# nRF7140_graphics register map
Vendor: Nordic Semiconductor; Series: nRF71; File version: 1
CPU: CM33 r0p4, little endian, MPU, FPU, 3 interrupt priority bits, 480 interrupts
Registers are 32-bit, read-write, reset 0x0 unless marked. A register's access mark holds for its fields unless they carry their own. Offsets are from the block's base; [hi:lo] are bit positions; lines under a group give offsets from that group; {n}, {i} and the like mark numbered series; 'fields as' and 'values as' point back to an identical list.

## GLOBAL_PWM120_NS — Pulse width modulation unit 0
Base 0x4F8E4000
Same registers: GLOBAL_PWM130_NS 0x4F9A4000, GLOBAL_PWM131_NS 0x4F9B4000, GLOBAL_PWM132_NS 0x4F9C4000, GLOBAL_PWM133_NS 0x4F9D4000, GLOBAL_PWM120_S 0x5F8E4000, GLOBAL_PWM130_S 0x5F9A4000, GLOBAL_PWM131_S 0x5F9B4000, GLOBAL_PWM132_S 0x5F9C4000, GLOBAL_PWM133_S 0x5F9D4000
0x00 TASKS_START wo — Starts PWM pulse generation with the last loaded values
  [0] TASKS_START
    1=Trigger task
0x04 TASKS_STOP wo — Stops PWM pulse generation on all channels at the end of current PWM period, and stops sequence playback
  [0] TASKS_STOP
    1=Trigger task
0x08 TASKS_NEXTSTEP wo — Steps by one value in the current sequence on all enabled channels if DECODER.MODE=NextStep. Does not cause PWM generation to start if not running.
  [0] TASKS_NEXTSTEP
    1=Trigger task
0x0C TASKS_SEQABORT wo — (Gracefully) aborts the playback of the current sequence or the current end delay
  [0] TASKS_SEQABORT
    1=Trigger task
0x10 TASKS_DMA group — Peripheral tasks.
  {0x0+8j} SEQ[{j}] (j=0..1) group — Peripheral tasks.
    0x00 START wo — Description cluster: Starts operation using easyDMA to load the values. See peripheral description for operation using easyDMA.
      [0] START — Starts operation using easyDMA to load the values. See peripheral description for operation using easyDMA.
        1=Trigger task
    0x04 STOP wo — Description cluster: Stops operation using easyDMA. This does not trigger an END event. After a STOP task, the easyDMA (channel) will also enter its lowest required power level.
      [0] STOP — Stops operation using easyDMA. This does not trigger an END event. After a STOP task, the easyDMA (channel) will also enter its lowest required power level.
        1=Trigger task
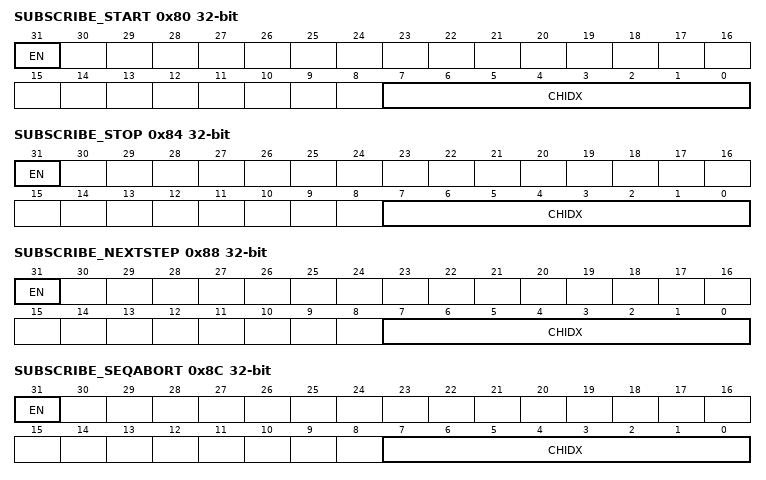
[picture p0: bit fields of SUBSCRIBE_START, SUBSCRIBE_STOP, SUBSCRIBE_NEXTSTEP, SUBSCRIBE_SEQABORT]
0x80 SUBSCRIBE_START — Subscribe configuration for task START
  [31] EN
    0=Disabled (Disable subscription); 1=Enabled (Enable subscription)
  [7:0] CHIDX — DPPI channel that task START will subscribe to
0x84 SUBSCRIBE_STOP — Subscribe configuration for task STOP
  [31] EN
    values as SUBSCRIBE_START.EN
  [7:0] CHIDX — DPPI channel that task STOP will subscribe to
0x88 SUBSCRIBE_NEXTSTEP — Subscribe configuration for task NEXTSTEP
  [31] EN
    values as SUBSCRIBE_START.EN
  [7:0] CHIDX — DPPI channel that task NEXTSTEP will subscribe to
0x8C SUBSCRIBE_SEQABORT — Subscribe configuration for task SEQABORT
  [31] EN
    values as SUBSCRIBE_START.EN
  [7:0] CHIDX — DPPI channel that task SEQABORT will subscribe to
0x90 SUBSCRIBE_DMA group — Subscribe configuration for tasks
  {0x0+8j} SEQ[{j}] (j=0..1) group — Subscribe configuration for tasks
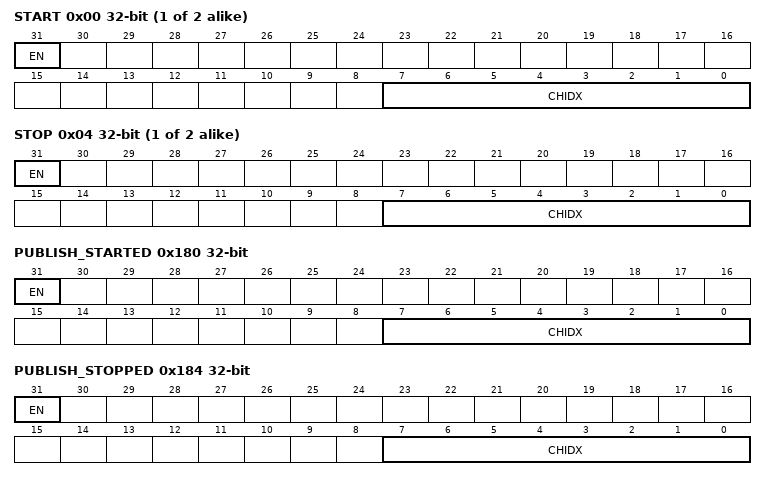
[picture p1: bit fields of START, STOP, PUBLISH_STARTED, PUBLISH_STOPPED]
    0x00 START — Description cluster: Subscribe configuration for task START
      fields as SUBSCRIBE_START
    0x04 STOP — Description cluster: Subscribe configuration for task STOP
      fields as SUBSCRIBE_STOP
0x100 EVENTS_STARTED — Response to START task, emitted when the PWM pulse generation starts
  [0] EVENTS_STARTED
    0=NotGenerated (Event not generated); 1=Generated (Event generated)
0x104 EVENTS_STOPPED — Response to STOP task, emitted when PWM pulses are no longer generated
  [0] EVENTS_STOPPED
    values as EVENTS_STARTED.EVENTS_STARTED
{0x108+4i} EVENTS_SEQSTARTED[{i}] (i=0..1) — Description collection: First PWM period started on sequence n
  [0] EVENTS_SEQSTARTED — First PWM period started on sequence n
    values as EVENTS_STARTED.EVENTS_STARTED
{0x110+4i} EVENTS_SEQEND[{i}] (i=0..1) — Description collection: Emitted at end of every sequence n, when last value from RAM has been applied to wave counter
  [0] EVENTS_SEQEND — Emitted at end of every sequence n, when last value from RAM has been applied to wave counter
    values as EVENTS_STARTED.EVENTS_STARTED
0x118 EVENTS_PWMPERIODEND — Emitted at the end of each PWM period
  [0] EVENTS_PWMPERIODEND
    values as EVENTS_STARTED.EVENTS_STARTED
0x11C EVENTS_LOOPSDONE — Concatenated sequences have been played the amount of times defined in LOOP.CNT
  [0] EVENTS_LOOPSDONE
    values as EVENTS_STARTED.EVENTS_STARTED
0x120 EVENTS_RAMUNDERFLOW — Emitted when retrieving from RAM does not complete in time for the PWM module
  [0] EVENTS_RAMUNDERFLOW
    values as EVENTS_STARTED.EVENTS_STARTED
0x124 EVENTS_DMA group — Peripheral events.
  {0x0+0xC*j} SEQ[{j}] (j=0..1) group — Peripheral events.
    0x00 END — Description cluster: Generated after all MAXCNT bytes have been transferred Equivalent to eventDmaEnd[Channel]
      [0] END — Generated after all MAXCNT bytes have been transferred Equivalent to eventDmaEnd[Channel]
        values as EVENTS_STARTED.EVENTS_STARTED
    0x04 READY — Description cluster: Generated when EasyDMA has buffered the .PTR and .MAXCNT registers for the channel, allowing them to be written to prepare for the next sequence.
      [0] READY — Generated when EasyDMA has buffered the .PTR and .MAXCNT registers for the channel, allowing them to be written to prepare for the next sequence.
        values as EVENTS_STARTED.EVENTS_STARTED
    0x08 BUSERROR — Description cluster: An error occured during the bus transfer. This event is generated on an AHB / AXI error response.
      [0] BUSERROR — An error occured during the bus transfer. This event is generated on an AHB / AXI error response.
        values as EVENTS_STARTED.EVENTS_STARTED
{0x13C+4i} EVENTS_COMPAREMATCH[{i}] (i=0..3) — Description collection: This event is generated when the compare matches for the compare channel [n].
  [0] EVENTS_COMPAREMATCH — This event is generated when the compare matches for the compare channel [n].
    values as EVENTS_STARTED.EVENTS_STARTED
0x180 PUBLISH_STARTED — Publish configuration for event STARTED
  [31] EN
    0=Disabled (Disable publishing); 1=Enabled (Enable publishing)
  [7:0] CHIDX — DPPI channel that event STARTED will publish to
0x184 PUBLISH_STOPPED — Publish configuration for event STOPPED
  [31] EN
    values as PUBLISH_STARTED.EN
  [7:0] CHIDX — DPPI channel that event STOPPED will publish to
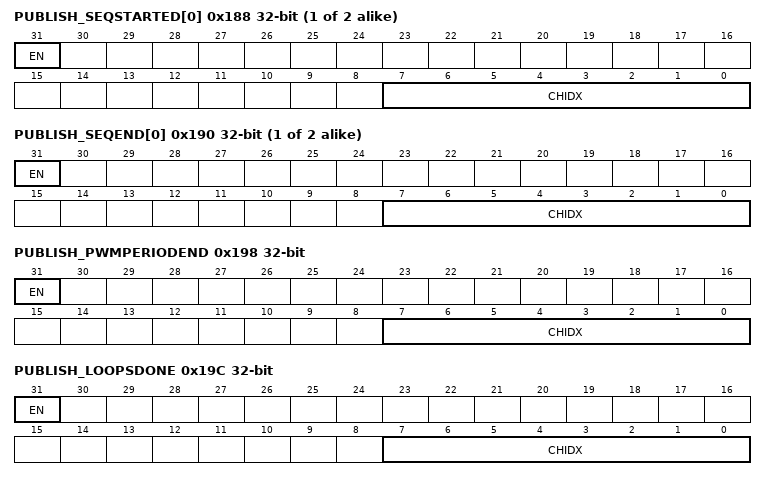
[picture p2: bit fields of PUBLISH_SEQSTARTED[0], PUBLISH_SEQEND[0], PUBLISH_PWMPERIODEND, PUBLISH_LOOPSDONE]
{0x188+4i} PUBLISH_SEQSTARTED[{i}] (i=0..1) — Description collection: Publish configuration for event SEQSTARTED[n]
  [31] EN
    values as PUBLISH_STARTED.EN
  [7:0] CHIDX — DPPI channel that event SEQSTARTED[n] will publish to
{0x190+4i} PUBLISH_SEQEND[{i}] (i=0..1) — Description collection: Publish configuration for event SEQEND[n]
  [31] EN
    values as PUBLISH_STARTED.EN
  [7:0] CHIDX — DPPI channel that event SEQEND[n] will publish to
0x198 PUBLISH_PWMPERIODEND — Publish configuration for event PWMPERIODEND
  [31] EN
    values as PUBLISH_STARTED.EN
  [7:0] CHIDX — DPPI channel that event PWMPERIODEND will publish to
0x19C PUBLISH_LOOPSDONE — Publish configuration for event LOOPSDONE
  [31] EN
    values as PUBLISH_STARTED.EN
  [7:0] CHIDX — DPPI channel that event LOOPSDONE will publish to
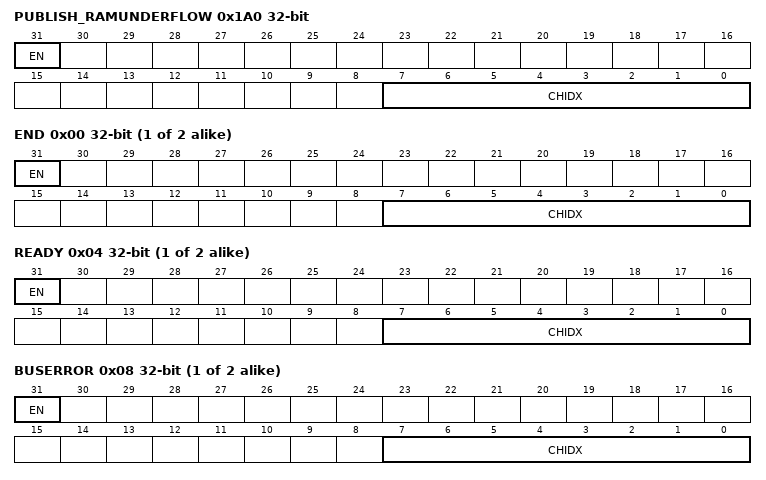
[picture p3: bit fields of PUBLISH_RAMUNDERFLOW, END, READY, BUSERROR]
0x1A0 PUBLISH_RAMUNDERFLOW — Publish configuration for event RAMUNDERFLOW
  [31] EN
    values as PUBLISH_STARTED.EN
  [7:0] CHIDX — DPPI channel that event RAMUNDERFLOW will publish to
0x1A4 PUBLISH_DMA group — Publish configuration for events
  {0x0+0xC*j} SEQ[{j}] (j=0..1) group — Publish configuration for events
    0x00 END — Description cluster: Publish configuration for event END
      [31] EN
        values as PUBLISH_STARTED.EN
      [7:0] CHIDX — DPPI channel that event END will publish to
    0x04 READY — Description cluster: Publish configuration for event READY
      [31] EN
        values as PUBLISH_STARTED.EN
      [7:0] CHIDX — DPPI channel that event READY will publish to
    0x08 BUSERROR — Description cluster: Publish configuration for event BUSERROR
      [31] EN
        values as PUBLISH_STARTED.EN
      [7:0] CHIDX — DPPI channel that event BUSERROR will publish to
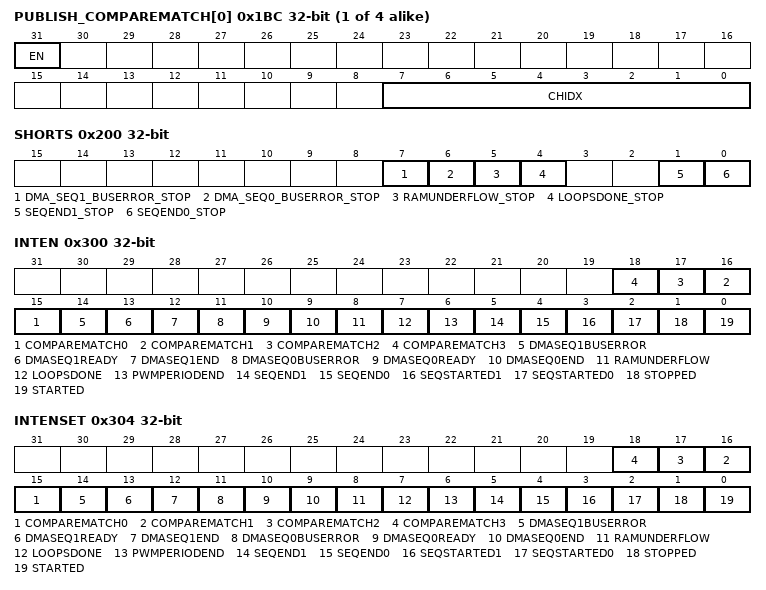
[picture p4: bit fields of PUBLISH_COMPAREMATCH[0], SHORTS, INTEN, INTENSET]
{0x1BC+4i} PUBLISH_COMPAREMATCH[{i}] (i=0..3) — Description collection: Publish configuration for event COMPAREMATCH[n]
  [31] EN
    values as PUBLISH_STARTED.EN
  [7:0] CHIDX — DPPI channel that event COMPAREMATCH[n] will publish to
0x200 SHORTS — Shortcuts between local events and tasks
  [all] fields
    0=Disabled (Disable shortcut); 1=Enabled (Enable shortcut)
  [7] DMA_SEQ1_BUSERROR_STOP — Shortcut between event DMA.SEQ[n].BUSERROR and task STOP
  [6] DMA_SEQ0_BUSERROR_STOP — Shortcut between event DMA.SEQ[n].BUSERROR and task STOP
  [5] RAMUNDERFLOW_STOP — Shortcut between event RAMUNDERFLOW and task STOP
  [4] LOOPSDONE_STOP — Shortcut between event LOOPSDONE and task STOP
  [1] SEQEND1_STOP — Shortcut between event SEQEND[n] and task STOP
  [0] SEQEND0_STOP — Shortcut between event SEQEND[n] and task STOP
0x300 INTEN — Enable or disable interrupt
  [all] fields
    0=Disabled; 1=Enabled
  [n+15] COMPAREMATCH{n} (n=0..3) — Enable or disable interrupt for event COMPAREMATCH[{n}]
  [14] DMASEQ1BUSERROR — Enable or disable interrupt for event DMASEQ1BUSERROR
  [13] DMASEQ1READY — Enable or disable interrupt for event DMASEQ1READY
  [12] DMASEQ1END — Enable or disable interrupt for event DMASEQ1END
  [11] DMASEQ0BUSERROR — Enable or disable interrupt for event DMASEQ0BUSERROR
  [10] DMASEQ0READY — Enable or disable interrupt for event DMASEQ0READY
  [9] DMASEQ0END — Enable or disable interrupt for event DMASEQ0END
  [8] RAMUNDERFLOW — Enable or disable interrupt for event RAMUNDERFLOW
  [7] LOOPSDONE — Enable or disable interrupt for event LOOPSDONE
  [6] PWMPERIODEND — Enable or disable interrupt for event PWMPERIODEND
  [5] SEQEND1 — Enable or disable interrupt for event SEQEND[1]
  [4] SEQEND0 — Enable or disable interrupt for event SEQEND[0]
  [3] SEQSTARTED1 — Enable or disable interrupt for event SEQSTARTED[1]
  [2] SEQSTARTED0 — Enable or disable interrupt for event SEQSTARTED[0]
  [1] STOPPED — Enable or disable interrupt for event STOPPED
  [0] STARTED — Enable or disable interrupt for event STARTED
0x304 INTENSET — Enable interrupt
  [all] fields
    on read: 0=Disabled (Read: Disabled); 1=Enabled (Read: Enabled) | on write: 1=Set (Enable)
  [n+15] COMPAREMATCH{n} (n=0..3) — Write '1' to enable interrupt for event COMPAREMATCH[{n}]
  [14] DMASEQ1BUSERROR — Write '1' to enable interrupt for event DMASEQ1BUSERROR
  [13] DMASEQ1READY — Write '1' to enable interrupt for event DMASEQ1READY
  [12] DMASEQ1END — Write '1' to enable interrupt for event DMASEQ1END
  [11] DMASEQ0BUSERROR — Write '1' to enable interrupt for event DMASEQ0BUSERROR
  [10] DMASEQ0READY — Write '1' to enable interrupt for event DMASEQ0READY
  [9] DMASEQ0END — Write '1' to enable interrupt for event DMASEQ0END
  [8] RAMUNDERFLOW — Write '1' to enable interrupt for event RAMUNDERFLOW
  [7] LOOPSDONE — Write '1' to enable interrupt for event LOOPSDONE
  [6] PWMPERIODEND — Write '1' to enable interrupt for event PWMPERIODEND
  [5] SEQEND1 — Write '1' to enable interrupt for event SEQEND[1]
  [4] SEQEND0 — Write '1' to enable interrupt for event SEQEND[0]
  [3] SEQSTARTED1 — Write '1' to enable interrupt for event SEQSTARTED[1]
  [2] SEQSTARTED0 — Write '1' to enable interrupt for event SEQSTARTED[0]
  [1] STOPPED — Write '1' to enable interrupt for event STOPPED
  [0] STARTED — Write '1' to enable interrupt for event STARTED
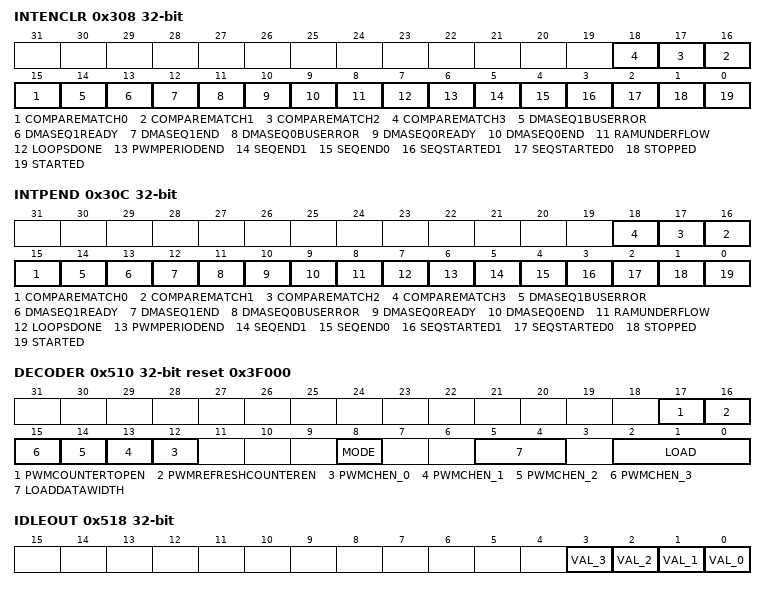
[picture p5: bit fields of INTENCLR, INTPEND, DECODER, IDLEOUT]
0x308 INTENCLR — Disable interrupt
  [all] fields
    on read: 0=Disabled (Read: Disabled); 1=Enabled (Read: Enabled) | on write: 1=Clear (Disable)
  [n+15] COMPAREMATCH{n} (n=0..3) — Write '1' to disable interrupt for event COMPAREMATCH[{n}]
  [14] DMASEQ1BUSERROR — Write '1' to disable interrupt for event DMASEQ1BUSERROR
  [13] DMASEQ1READY — Write '1' to disable interrupt for event DMASEQ1READY
  [12] DMASEQ1END — Write '1' to disable interrupt for event DMASEQ1END
  [11] DMASEQ0BUSERROR — Write '1' to disable interrupt for event DMASEQ0BUSERROR
  [10] DMASEQ0READY — Write '1' to disable interrupt for event DMASEQ0READY
  [9] DMASEQ0END — Write '1' to disable interrupt for event DMASEQ0END
  [8] RAMUNDERFLOW — Write '1' to disable interrupt for event RAMUNDERFLOW
  [7] LOOPSDONE — Write '1' to disable interrupt for event LOOPSDONE
  [6] PWMPERIODEND — Write '1' to disable interrupt for event PWMPERIODEND
  [5] SEQEND1 — Write '1' to disable interrupt for event SEQEND[1]
  [4] SEQEND0 — Write '1' to disable interrupt for event SEQEND[0]
  [3] SEQSTARTED1 — Write '1' to disable interrupt for event SEQSTARTED[1]
  [2] SEQSTARTED0 — Write '1' to disable interrupt for event SEQSTARTED[0]
  [1] STOPPED — Write '1' to disable interrupt for event STOPPED
  [0] STARTED — Write '1' to disable interrupt for event STARTED
0x30C INTPEND ro — Pending interrupts
  [all] fields
    on read: 0=NotPending (Read: Not pending); 1=Pending (Read: Pending)
  [n+15] COMPAREMATCH{n} (n=0..3) — Read pending status of interrupt for event COMPAREMATCH[{n}]
  [14] DMASEQ1BUSERROR — Read pending status of interrupt for event DMASEQ1BUSERROR
  [13] DMASEQ1READY — Read pending status of interrupt for event DMASEQ1READY
  [12] DMASEQ1END — Read pending status of interrupt for event DMASEQ1END
  [11] DMASEQ0BUSERROR — Read pending status of interrupt for event DMASEQ0BUSERROR
  [10] DMASEQ0READY — Read pending status of interrupt for event DMASEQ0READY
  [9] DMASEQ0END — Read pending status of interrupt for event DMASEQ0END
  [8] RAMUNDERFLOW — Read pending status of interrupt for event RAMUNDERFLOW
  [7] LOOPSDONE — Read pending status of interrupt for event LOOPSDONE
  [6] PWMPERIODEND — Read pending status of interrupt for event PWMPERIODEND
  [5] SEQEND1 — Read pending status of interrupt for event SEQEND[1]
  [4] SEQEND0 — Read pending status of interrupt for event SEQEND[0]
  [3] SEQSTARTED1 — Read pending status of interrupt for event SEQSTARTED[1]
  [2] SEQSTARTED0 — Read pending status of interrupt for event SEQSTARTED[0]
  [1] STOPPED — Read pending status of interrupt for event STOPPED
  [0] STARTED — Read pending status of interrupt for event STARTED
0x500 ENABLE — PWM module enable register
  [0] ENABLE — Enable or disable PWM module
    0=Disabled; 1=Enabled
0x504 MODE — Selects operating mode of the wave counter
  [0] UPDOWN — Selects up mode or up-and-down mode for the counter
    0=Up (Up counter, edge-aligned PWM duty cycle); 1=Up and down counter, center-aligned PWM duty cycle
0x508 COUNTERTOP reset 0x3FF — Value up to which the pulse generator counter counts
  [14:0] COUNTERTOP — Value up to which the pulse generator counter counts. This register is ignored when DECODER.MODE=WaveForm and only values from RAM are used.
0x50C PRESCALER — Configuration for PWM_CLK
  [2:0] PRESCALER — Prescaler of PWM_CLK
    0=DIV_1 (Divide by 1 (16 MHz)); 1=DIV_2 (Divide by 2 (8 MHz)); 2=DIV_4 (Divide by 4 (4 MHz)); 3=DIV_8 (Divide by 8 (2 MHz)); 4=DIV_16 (Divide by 16 (1 MHz)); 5=DIV_32 (Divide by 32 (500 kHz)); 6=DIV_64 (Divide by 64 (250 kHz)); 7=DIV_128 (Divide by 128 (125 kHz))
0x510 DECODER reset 0x3F000 — Configuration of the decoder
  [17] PWMCOUNTERTOPEN — PWM COUNTERTOP enable configuration for the sequence
    0=Disable (PWM COUNTERTOP disabled); 1=Enable (PWM COUNTERTOP enabled)
  [16] PWMREFRESHCOUNTEREN — PWM Refresh counter enable configuration for the sequence
    0=Disable (PWM Refresh counter disabled); 1=Enable (PWM Refresh counter enabled)
  [n+12] PWMCHEN_{n} (n=0..3) — PWM channel [{n}] enable configuration for the sequence
    0=Disable (PWM channel disabled); 1=Enable (PWM channel enabled)
  [8] MODE — Selects source for advancing the active sequence
    0=RefreshCount (SEQ[n].REFRESH is used to determine loading internal compare registers); 1=NEXTSTEP task causes a new value to be loaded to internal compare registers
  [5:4] LOADDATAWIDTH — Load data width of sequence read from RAM
    0=Load data width is 16 bit; 1=Load data width is 8 bit; 2=Load data width is 4 bit
  [2:0] LOAD — How a sequence is read from RAM and spread to the compare register
    0=Common (1st half word (16-bit) used in all PWM channels 0..3); 1=Grouped (1st half word (16-bit) used in channel 0..1; 2nd word in channel 2..3); 2=Individual (1st half word (16-bit) in ch.0; 2nd in ch.1; ...; 4th in ch.3); 3=WaveForm (1st half word (16-bit) in ch.0; 2nd in ch.1; ...; 4th in COUNTERTOP); 4=WaveformRefresh (1st half word (16-bit) in ch.0; 2nd in ch.1; 3rd in refresh count; 4th in COUNTERTOP)
0x514 LOOP — Number of playbacks of a loop
  [15:0] CNT — Number of playbacks of pattern cycles
    0=Disabled (Looping disabled (stop at the end of the sequence))
0x518 IDLEOUT — Configure the output value on the PWM channel during idle
  [n] VAL_{n} (n=0..3) — Idle output value for PWM channel [{n}]
{0x520+0x20*i} SEQ[{i}] (i=0..1) group — Unspecified
  0x04 CNT — Description cluster: Number of values (duty cycles) in this sequence
    [14:0] CNT — Number of values (duty cycles) in this sequence
      0=Disabled (Sequence is disabled, and shall not be started as it is empty)
  0x08 REFRESH reset 0x1 — Description cluster: Number of additional PWM periods between samples loaded into compare register
    [23:0] CNT — Number of additional PWM periods between samples loaded into compare register (load every REFRESH.CNT+1 PWM periods)
      0=Continuous (Update every PWM period)
  0x0C ENDDELAY — Description cluster: Time added after the sequence
    [23:0] CNT — Time added after the sequence in PWM periods
0x560 PSEL group — Unspecified
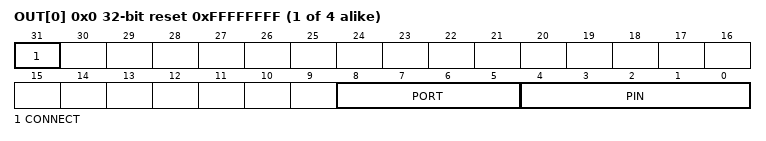
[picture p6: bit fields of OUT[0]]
  {0x0+4j} OUT[{j}] (j=0..3) reset 0xFFFFFFFF — Description collection: Output pin select for PWM channel n
    [31] CONNECT — Connection
      1=Disconnected; 0=Connected
    [8:5] PORT — Port number
    [4:0] PIN — Pin number
0x700 DMA group — Unspecified
  {0x0+0x24*j} SEQ[{j}] (j=0..1) group — Unspecified
    0x00 ENABLE — Description cluster: Register doesn't do anything. Can be written and read, but has no functionality attached.
      [0] ENABLE — Register doesn't do anything. Can be written and read, but has no functionality attached.
        0=Disabled; 1=Enabled
    0x04 PTR — Description cluster: RAM buffer start address
      [31:0] PTR — RAM buffer start address for this EasyDMA channel. This address is a word aligned Data RAM address.
    0x08 MAXCNT — Description cluster: Maximum number of bytes in receive buffer
      [15:0] MAXCNT — Maximum number of bytes in receive buffer
    0x0C AMOUNT ro — Description cluster: Number of bytes transferred in the last transaction, updated after the END event.
      [15:0] AMOUNT — Number of bytes transferred in the last transaction. In case of NACK error, includes the NACK'ed byte.
    0x1C TERMINATEONBUSERROR — Description cluster: Terminate the transaction if a BUSERROR event is detected.
      [0] ENABLE
        0=Disabled; 1=Enabled
    0x20 BUSERRORADDRESS — Description cluster: Address of transaction that generated the last BUSERROR event.
      [31:0] ADDRESS
